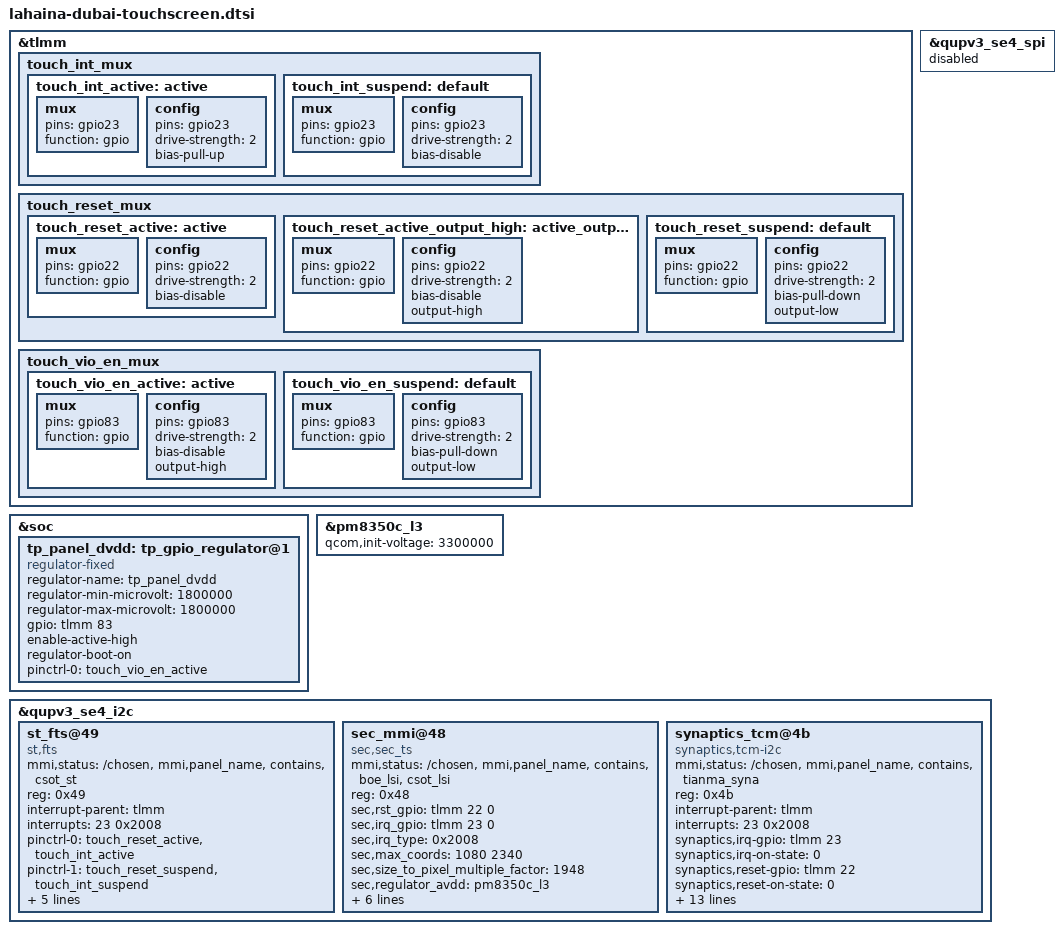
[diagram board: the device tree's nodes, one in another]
&tlmm {
	touch_int_mux {
		touch_int_active: active {
			mux {
				pins = "gpio23";
				function = "gpio";
			};
			config {
				pins = "gpio23";
				drive-strength = <2>;
				bias-pull-up;
			};
		};

		touch_int_suspend: default {
			mux {
				pins = "gpio23";
				function = "gpio";
			};
			config {
				pins = "gpio23";
				drive-strength = <2>;
				bias-disable;
			};
		};
	};

	touch_reset_mux {
		touch_reset_active: active {
			mux {
				pins = "gpio22";
				function = "gpio";
			};
			config {
				pins = "gpio22";
				drive-strength = <2>;
				bias-disable;
			};
		};

		touch_reset_active_output_high: active_output_high {
			mux {
				pins = "gpio22";
				function = "gpio";
			};
			config {
				pins = "gpio22";
				drive-strength = <2>;
				bias-disable;
				output-high;
			};
		};

		touch_reset_suspend: default {
			mux {
				pins = "gpio22";
				function = "gpio";
			};
			config {
				pins = "gpio22";
				drive-strength = <2>;
				bias-pull-down;
				output-low;
			};
		};
	};

	touch_vio_en_mux {
		touch_vio_en_active: active {
			mux {
				pins = "gpio83";
				function = "gpio";
			};
			config {
				pins = "gpio83";
				drive-strength = <2>;
				bias-disable;
				output-high;
			};
		};

		touch_vio_en_suspend: default {
			mux {
				pins = "gpio83";
				function = "gpio";
			};
			config {
				pins = "gpio83";
				drive-strength = <2>;
				bias-pull-down;
				output-low;
			};
		};
	};
};

&soc {
	tp_panel_dvdd: tp_gpio_regulator@1 {
		compatible = "regulator-fixed";
		regulator-name = "tp_panel_dvdd";
		regulator-min-microvolt = <1800000>;
		regulator-max-microvolt = <1800000>;
		gpio = <&tlmm 83 0>;
		enable-active-high;
		regulator-boot-on;
		pinctrl-names = "default";
		pinctrl-0 = <&touch_vio_en_active>;
	};
};

&pm8350c_l3 {
	qcom,init-voltage = <3300000>;
};

&qupv3_se4_spi {
	status = "disabled";
};

&qupv3_se4_i2c {
	status = "ok";

	st_fts@49 {
		status = "ok";
		mmi,status = "/chosen","mmi,panel_name","contains","csot_st";
		compatible = "st,fts";
		reg = <0x49>;
		interrupt-parent = <&tlmm>;
		interrupts = <23 0x2008>;
		pinctrl-names = "pmx_ts_active", "pmx_ts_suspend";
		pinctrl-0 = <&touch_reset_active &touch_int_active>;
		pinctrl-1 = <&touch_reset_suspend &touch_int_suspend>;
		st,reset-gpio = <&tlmm 22 0>;
		st,irq-gpio = <&tlmm 23 0x2008>;
		st,regulator_avdd = "pm8350c_l3";
		st,regulator_dvdd = "tp_panel_dvdd";
		panel = <&mot_csot_st_667_1080p_cmd>;
	};

	sec_mmi@48 {
		status = "ok";
		mmi,status = "/chosen","mmi,panel_name","contains","boe_lsi","csot_lsi";
		compatible = "sec,sec_ts";
		reg = <0x48>;
		sec,rst_gpio = <&tlmm 22 0>;
		sec,irq_gpio = <&tlmm 23 0>;
		sec,irq_type = <0x2008>; /*IRQF_TRIGGER_LOW | IRQF_ONESHOT*/
		sec,max_coords = <1080 2340>;
		sec,size_to_pixel_multiple_factor = <1948>;
		sec,regulator_avdd = "pm8350c_l3";
		sec,regulator_dvdd = "tp_panel_dvdd";
		pinctrl-names = "on_state", "off_state";
		pinctrl-0 = <&touch_reset_active &touch_int_active>;
		pinctrl-1 = <&touch_reset_suspend &touch_int_suspend>;
		panel = <&mot_boe_667_1080p_cmd_v0>;
	};

	synaptics_tcm@4b {
		status = "ok";
		mmi,status = "/chosen","mmi,panel_name","contains","tianma_syna";
		compatible = "synaptics,tcm-i2c";
		reg = <0x4b>;
		interrupt-parent = <&tlmm>;
		interrupts = <23 0x2008>;
		synaptics,irq-gpio = <&tlmm 23 0x2008>; /*IRQF_TRIGGER_LOW | IRQF_ONESHOT*/
		synaptics,irq-on-state = <0>;
		synaptics,reset-gpio = <&tlmm 22 0x0000>;
		synaptics,reset-on-state = <0>;
		synaptics,reset-active-ms = <20>;
		synaptics,reset-delay-ms = <200>;
		synaptics,power-delay-ms = <200>;
		synaptics,ubl-i2c-addr = <0x4b>;
		synaptics,size_to_pixel_multiple_factor = <1948>;
		synaptics,pwr-reg-name = "pm8350c_l3";
		synaptics,bus-reg-name = "tp_panel_dvdd";
		pinctrl-names = "ts_mmi_on_state", "ts_mmi_off_state";
		pinctrl-0 = <&touch_reset_active_output_high &touch_int_active>;
		pinctrl-1 = <&touch_reset_suspend &touch_int_suspend>;
		/* touchscreen_mmi class entries */
		mmi,max_coords = <1080 2340>;
		panel = <&mot_tianma_syna_667_1080p_cmd_v1>;
	};
};
